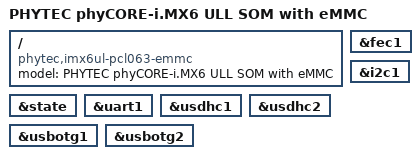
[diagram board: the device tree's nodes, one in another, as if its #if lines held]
// SPDX-License-Identifier: (GPL-2.0-or-later OR MIT)
/*
 * Copyright (C) 2019 PHYTEC Messtechnik GmbH
 * Author: Stefan Riedmueller <s.riedmueller@phytec.de>
 */

/dts-v1/;
#ifdef CONFIG_BOOTM_FITIMAGE_PUBKEY
#include CONFIG_BOOTM_FITIMAGE_PUBKEY
#endif
#include <arm/imx6ull.dtsi>
#include "imx6ul-phytec-phycore-som.dtsi"
#include "imx6ul-phytec-state.dtsi"

/ {
	model = "PHYTEC phyCORE-i.MX6 ULL SOM with eMMC";
	compatible = "phytec,imx6ul-pcl063-emmc", "fsl,imx6ull";
};

&fec1 {
	status = "okay";
};

&i2c1 {
	status = "okay";
};

&state {
        status = "okay";
};

&uart1 {
	status = "okay";
};

&usdhc1 {
	status = "okay";
};

&usdhc2 {
	status = "okay";
};

&usbotg1 {
	status = "okay";
};

&usbotg2 {
	status = "okay";
};
